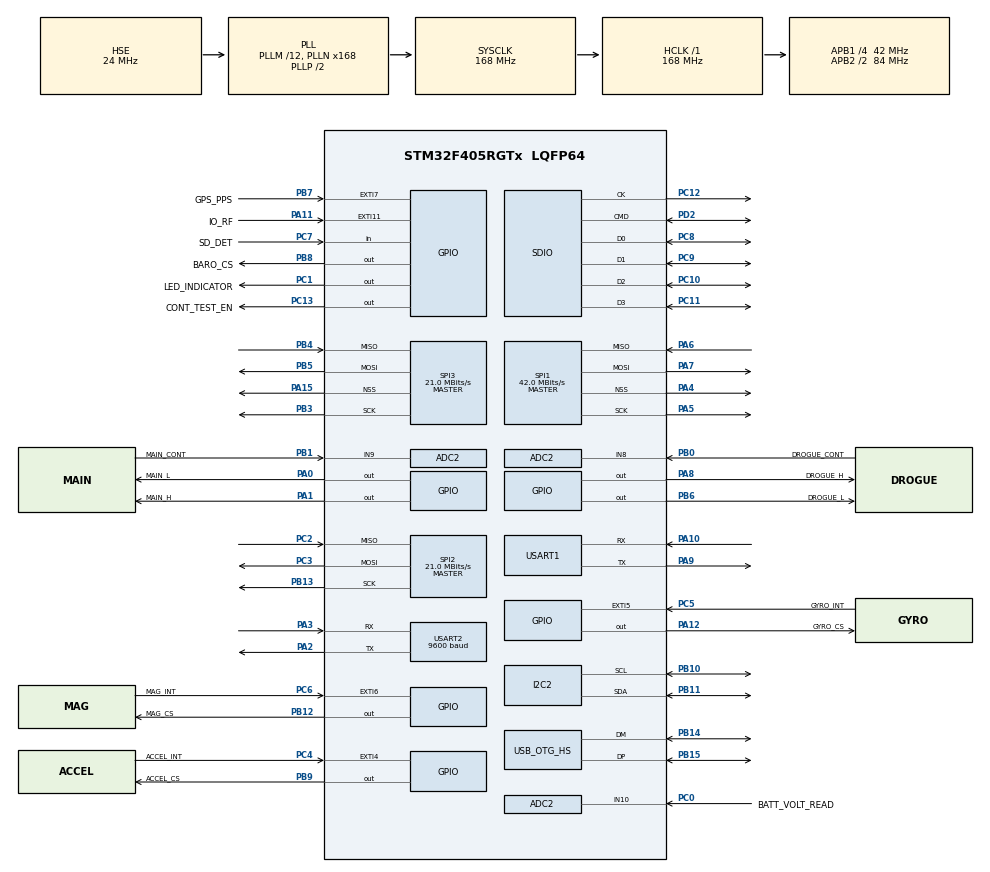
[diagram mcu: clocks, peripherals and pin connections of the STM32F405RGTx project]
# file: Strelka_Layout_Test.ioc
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ADC2.Channel-0\#ChannelRegularConversion=ADC_CHANNEL_8
ADC2.NbrOfConversionFlag=1
ADC2.Rank-0\#ChannelRegularConversion=1
ADC2.SamplingTime-0\#ChannelRegularConversion=ADC_SAMPLETIME_3CYCLES
FATFS.BSP.number=1
FATFS0.BSP.STBoard=false
FATFS0.BSP.api=Unknown
FATFS0.BSP.instance=PC7
FATFS0.BSP.ip=GPIO
FATFS0.BSP.mode=Input
FATFS0.BSP.name=Detect_SDIO
FATFS0.BSP.solution=PC7
FREERTOS.Tasks01=defaultTask,24,128,StartDefaultTask,Default,NULL,Dynamic,NULL,NULL
I2C2.I2C_Mode=I2C_Fast
Mcu.Family=STM32F4
Mcu.Name=STM32F405RGTx
Mcu.Package=LQFP64
NVIC.OTG_HS_IRQn=true\:5\:0\:false\:false\:true\:true\:false\:true\:true
NVIC.PriorityGroup=NVIC_PRIORITYGROUP_4
PA0-WKUP.GPIO_Label=MAIN_L
PA0-WKUP.Signal=GPIO_Output
PA1.GPIO_Label=MAIN_H
PA1.Signal=GPIO_Output
PA10.Mode=Asynchronous
PA10.Signal=USART1_RX
PA11.GPIO_Label=IO_RF
PA11.Signal=GPXTI11
PA12.GPIO_Label=GYRO_CS
PA12.Signal=GPIO_Output
PA13.Mode=Serial_Wire
PA13.Signal=SYS_JTMS-SWDIO
PA14.Mode=Serial_Wire
PA14.Signal=SYS_JTCK-SWCLK
PA15.Mode=NSS_Signal_Hard_Output
PA15.Signal=SPI3_NSS
PA2.Mode=Asynchronous
PA2.Signal=USART2_TX
PA3.Mode=Asynchronous
PA3.Signal=USART2_RX
PA4.Mode=NSS_Signal_Hard_Output
PA4.Signal=SPI1_NSS
PA5.Mode=Full_Duplex_Master
PA5.Signal=SPI1_SCK
PA6.Mode=Full_Duplex_Master
PA6.Signal=SPI1_MISO
PA7.Mode=Full_Duplex_Master
PA7.Signal=SPI1_MOSI
PA8.GPIO_Label=DROGUE_H
PA8.Signal=GPIO_Output
PA9.Mode=Asynchronous
PA9.Signal=USART1_TX
PB0.GPIO_Label=DROGUE_CONT
PB0.Signal=ADCx_IN8
PB1.GPIO_Label=MAIN_CONT
PB1.Signal=ADCx_IN9
PB10.Mode=I2C
PB10.Signal=I2C2_SCL
PB11.Mode=I2C
PB11.Signal=I2C2_SDA
PB12.GPIO_Label=MAG_CS
PB12.Signal=GPIO_Output
PB13.Mode=Full_Duplex_Master
PB13.Signal=SPI2_SCK
PB14.Mode=Device_Only_FS
PB14.Signal=USB_OTG_HS_DM
PB15.Mode=Device_Only_FS
PB15.Signal=USB_OTG_HS_DP
PB3.Mode=Full_Duplex_Master
PB3.Signal=SPI3_SCK
PB4.Mode=Full_Duplex_Master
PB4.Signal=SPI3_MISO
PB5.Mode=Full_Duplex_Master
PB5.Signal=SPI3_MOSI
PB6.GPIO_Label=DROGUE_L
PB6.Signal=GPIO_Output
PB7.GPIO_Label=GPS_PPS
PB7.Signal=GPXTI7
PB8.GPIO_Label=BARO_CS
PB8.Signal=GPIO_Output
PB9.GPIO_Label=ACCEL_CS
PB9.Signal=GPIO_Output
PC0.GPIO_Label=BATT_VOLT_READ
PC0.Signal=ADCx_IN10
PC1.GPIO_Label=LED_INDICATOR
PC1.Signal=GPIO_Output
PC10.Mode=SD_4_bits_Wide_bus
PC10.Signal=SDIO_D2
PC11.Mode=SD_4_bits_Wide_bus
PC11.Signal=SDIO_D3
PC12.Mode=SD_4_bits_Wide_bus
PC12.Signal=SDIO_CK
PC13-ANTI_TAMP.GPIO_Label=CONT_TEST_EN
PC13-ANTI_TAMP.Signal=GPIO_Output
PC14-OSC32_IN.Mode=LSE-External-Oscillator
PC14-OSC32_IN.Signal=RCC_OSC32_IN
PC15-OSC32_OUT.Mode=LSE-External-Oscillator
PC15-OSC32_OUT.Signal=RCC_OSC32_OUT
PC2.Mode=Full_Duplex_Master
PC2.Signal=SPI2_MISO
PC3.Mode=Full_Duplex_Master
PC3.Signal=SPI2_MOSI
PC4.GPIO_Label=ACCEL_INT
PC4.Signal=GPXTI4
PC5.GPIO_Label=GYRO_INT
PC5.Signal=GPXTI5
PC6.GPIO_Label=MAG_INT
PC6.Signal=GPXTI6
PC7.GPIO_Label=SD_DET
PC7.Signal=GPIO_Input
PC8.Mode=SD_4_bits_Wide_bus
PC8.Signal=SDIO_D0
PC9.Mode=SD_4_bits_Wide_bus
PC9.Signal=SDIO_D1
PD2.Mode=SD_4_bits_Wide_bus
PD2.Signal=SDIO_CMD
PH0-OSC_IN.Mode=HSE-External-Oscillator
PH0-OSC_IN.Signal=RCC_OSC_IN
PH1-OSC_OUT.Mode=HSE-External-Oscillator
PH1-OSC_OUT.Signal=RCC_OSC_OUT
ProjectManager.HeapSize=0x200
ProjectManager.StackSize=0x400
ProjectManager.TargetToolchain=STM32CubeIDE
RCC.48MHZClocksFreq_Value=48000000
RCC.AHBFreq_Value=168000000
RCC.APB1CLKDivider=RCC_HCLK_DIV4
RCC.APB1Freq_Value=42000000
RCC.APB1TimFreq_Value=84000000
RCC.APB2CLKDivider=RCC_HCLK_DIV2
RCC.APB2Freq_Value=84000000
RCC.APB2TimFreq_Value=168000000
RCC.CortexFreq_Value=168000000
RCC.HCLKFreq_Value=168000000
RCC.HSE_VALUE=24000000
RCC.HSI_VALUE=16000000
RCC.PLLM=12
RCC.PLLN=168
RCC.PLLQ=7
RCC.SYSCLKFreq_VALUE=168000000
RCC.SYSCLKSource=RCC_SYSCLKSOURCE_PLLCLK
RCC.VCOOutputFreq_Value=336000000
SH.ADCx_IN10.0=ADC2_IN10,IN10
SH.ADCx_IN8.0=ADC2_IN8,IN8
SH.ADCx_IN9.0=ADC2_IN9,IN9
SPI1.BaudRatePrescaler=SPI_BAUDRATEPRESCALER_2
SPI1.CalculateBaudRate=42.0 MBits/s
SPI1.Direction=SPI_DIRECTION_2LINES
SPI1.Mode=SPI_MODE_MASTER
SPI1.VirtualNSS=VM_NSSHARD
SPI1.VirtualType=VM_MASTER
SPI2.BaudRatePrescaler=SPI_BAUDRATEPRESCALER_2
SPI2.CalculateBaudRate=21.0 MBits/s
SPI2.Direction=SPI_DIRECTION_2LINES
SPI2.Mode=SPI_MODE_MASTER
SPI2.VirtualType=VM_MASTER
SPI3.BaudRatePrescaler=SPI_BAUDRATEPRESCALER_2
SPI3.CRCCalculation=SPI_CRCCALCULATION_DISABLE
SPI3.CalculateBaudRate=21.0 MBits/s
SPI3.Direction=SPI_DIRECTION_2LINES
SPI3.Mode=SPI_MODE_MASTER
SPI3.VirtualNSS=VM_NSSHARD
SPI3.VirtualType=VM_MASTER
USART1.VirtualMode=VM_ASYNC
USART2.BaudRate=9600
USART2.VirtualMode=VM_ASYNC
USB_DEVICE.CLASS_NAME_HS=CDC
USB_DEVICE.VirtualMode-CDC_HS=Cdc
USB_DEVICE.VirtualModeHS=Cdc_HS
USB_OTG_HS.VirtualMode-Device_Only_FS=Device_Only_FS
VP_CRC_VS_CRC.Mode=CRC_Activate
VP_FATFS_VS_SDIO.Mode=SDIO
VP_FREERTOS_VS_CMSIS_V2.Mode=CMSIS_V2
VP_TIM3_VS_ClockSourceINT.Mode=Internal
VP_USB_DEVICE_VS_USB_DEVICE_CDC_HS.Mode=CDC_HS
board=custom

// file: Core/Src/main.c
/* USER CODE BEGIN Header */
/**
  ******************************************************************************
  * @file           : main.c
  * @brief          : Main program body
  ******************************************************************************
  * @attention
  *
  * Copyright (c) 2022 STMicroelectronics.
  * All rights reserved.
  *
  * This software is licensed under terms that can be found in the LICENSE file
  * in the root directory of this software component.
  * If no LICENSE file comes with this software, it is provided AS-IS.
  *
  ******************************************************************************
  */
/* USER CODE END Header */
#include "main.h"
#include "cmsis_os.h"
#include "fatfs.h"
#include "usb_device.h"

/* USER CODE BEGIN Includes */
#include "actuator_control.h"
#include "bmx055.h"
#include "data_logging.h"
#include "Ematch_actuators.h"
#include "max_m10.h"
#include "ms5611.h"
/* USER CODE END Includes */

ADC_HandleTypeDef hadc2;

CRC_HandleTypeDef hcrc;

I2C_HandleTypeDef hi2c2;

SD_HandleTypeDef hsd;

SPI_HandleTypeDef hspi1;
SPI_HandleTypeDef hspi2;
SPI_HandleTypeDef hspi3;

TIM_HandleTypeDef htim3;

UART_HandleTypeDef huart1;
UART_HandleTypeDef huart2;

/* Definitions for defaultTask */
osThreadId_t defaultTaskHandle;
const osThreadAttr_t defaultTask_attributes = {
  .name = "defaultTask",
  .stack_size = 128 * 4,
  .priority = (osPriority_t) osPriorityNormal,
};

void SystemClock_Config(void);
static void MX_GPIO_Init(void);
static void MX_SDIO_SD_Init(void);
static void MX_SPI1_Init(void);
static void MX_SPI2_Init(void);
static void MX_USART1_UART_Init(void);
static void MX_TIM3_Init(void);
static void MX_I2C2_Init(void);
static void MX_ADC2_Init(void);
static void MX_SPI3_Init(void);
static void MX_USART2_UART_Init(void);
static void MX_CRC_Init(void);
void StartDefaultTask(void *argument);

int main(void)
{

  /* MCU Configuration--------------------------------------------------------*/

  /* Reset of all peripherals, Initializes the Flash interface and the Systick. */
  HAL_Init();

  /* Configure the system clock */
  SystemClock_Config();

  /* Initialize all configured peripherals */
  MX_GPIO_Init();
  MX_SDIO_SD_Init();
  MX_SPI1_Init();
  MX_SPI2_Init();
  MX_USART1_UART_Init();
  MX_TIM3_Init();
  MX_FATFS_Init();
  MX_I2C2_Init();
  MX_ADC2_Init();
  MX_SPI3_Init();
  MX_USART2_UART_Init();
  MX_CRC_Init();

  /* Init scheduler */
  osKernelInitialize();

  /* Create the thread(s) */
  /* creation of defaultTask */
  defaultTaskHandle = osThreadNew(StartDefaultTask, NULL, &defaultTask_attributes);

  /* Start scheduler */
  osKernelStart();

  /* We should never get here as control is now taken by the scheduler */
  /* Infinite loop */
  while (1)
  {

  }
}

void SystemClock_Config(void)
{
  RCC_OscInitTypeDef RCC_OscInitStruct = {0};
  RCC_ClkInitTypeDef RCC_ClkInitStruct = {0};

  /** Configure the main internal regulator output voltage
  */
  __HAL_RCC_PWR_CLK_ENABLE();
  __HAL_PWR_VOLTAGESCALING_CONFIG(PWR_REGULATOR_VOLTAGE_SCALE1);

  /** Initializes the RCC Oscillators according to the specified parameters
  * in the RCC_OscInitTypeDef structure.
  */
  RCC_OscInitStruct.OscillatorType = RCC_OSCILLATORTYPE_HSE;
  RCC_OscInitStruct.HSEState = RCC_HSE_ON;
  RCC_OscInitStruct.PLL.PLLState = RCC_PLL_ON;
  RCC_OscInitStruct.PLL.PLLSource = RCC_PLLSOURCE_HSE;
  RCC_OscInitStruct.PLL.PLLM = 12;
  RCC_OscInitStruct.PLL.PLLN = 168;
  RCC_OscInitStruct.PLL.PLLP = RCC_PLLP_DIV2;
  RCC_OscInitStruct.PLL.PLLQ = 7;
  if (HAL_RCC_OscConfig(&RCC_OscInitStruct) != HAL_OK)
  {
    Error_Handler();
  }

  /** Initializes the CPU, AHB and APB buses clocks
  */
  RCC_ClkInitStruct.ClockType = RCC_CLOCKTYPE_HCLK|RCC_CLOCKTYPE_SYSCLK
                              |RCC_CLOCKTYPE_PCLK1|RCC_CLOCKTYPE_PCLK2;
  RCC_ClkInitStruct.SYSCLKSource = RCC_SYSCLKSOURCE_PLLCLK;
  RCC_ClkInitStruct.AHBCLKDivider = RCC_SYSCLK_DIV1;
  RCC_ClkInitStruct.APB1CLKDivider = RCC_HCLK_DIV4;
  RCC_ClkInitStruct.APB2CLKDivider = RCC_HCLK_DIV2;

  if (HAL_RCC_ClockConfig(&RCC_ClkInitStruct, FLASH_LATENCY_5) != HAL_OK)
  {
    Error_Handler();
  }
}

static void MX_ADC2_Init(void)
{

  ADC_ChannelConfTypeDef sConfig = {0};

  /** Configure the global features of the ADC (Clock, Resolution, Data Alignment and number of conversion)
  */
  hadc2.Instance = ADC2;
  hadc2.Init.ClockPrescaler = ADC_CLOCK_SYNC_PCLK_DIV4;
  hadc2.Init.Resolution = ADC_RESOLUTION_12B;
  hadc2.Init.ScanConvMode = DISABLE;
  hadc2.Init.ContinuousConvMode = DISABLE;
  hadc2.Init.DiscontinuousConvMode = DISABLE;
  hadc2.Init.ExternalTrigConvEdge = ADC_EXTERNALTRIGCONVEDGE_NONE;
  hadc2.Init.ExternalTrigConv = ADC_SOFTWARE_START;
  hadc2.Init.DataAlign = ADC_DATAALIGN_RIGHT;
  hadc2.Init.NbrOfConversion = 1;
  hadc2.Init.DMAContinuousRequests = DISABLE;
  hadc2.Init.EOCSelection = ADC_EOC_SINGLE_CONV;
  if (HAL_ADC_Init(&hadc2) != HAL_OK)
  {
    Error_Handler();
  }

  /** Configure for the selected ADC regular channel its corresponding rank in the sequencer and its sample time.
  */
  sConfig.Channel = ADC_CHANNEL_8;
  sConfig.Rank = 1;
  sConfig.SamplingTime = ADC_SAMPLETIME_3CYCLES;
  if (HAL_ADC_ConfigChannel(&hadc2, &sConfig) != HAL_OK)
  {
    Error_Handler();
  }

}

static void MX_CRC_Init(void)
{

  hcrc.Instance = CRC;
  if (HAL_CRC_Init(&hcrc) != HAL_OK)
  {
    Error_Handler();
  }

}

static void MX_I2C2_Init(void)
{

  hi2c2.Instance = I2C2;
  hi2c2.Init.ClockSpeed = 400000;
  hi2c2.Init.DutyCycle = I2C_DUTYCYCLE_2;
  hi2c2.Init.OwnAddress1 = 0;
  hi2c2.Init.AddressingMode = I2C_ADDRESSINGMODE_7BIT;
  hi2c2.Init.DualAddressMode = I2C_DUALADDRESS_DISABLE;
  hi2c2.Init.OwnAddress2 = 0;
  hi2c2.Init.GeneralCallMode = I2C_GENERALCALL_DISABLE;
  hi2c2.Init.NoStretchMode = I2C_NOSTRETCH_DISABLE;
  if (HAL_I2C_Init(&hi2c2) != HAL_OK)
  {
    Error_Handler();
  }

}

static void MX_SDIO_SD_Init(void)
{

  hsd.Instance = SDIO;
  hsd.Init.ClockEdge = SDIO_CLOCK_EDGE_RISING;
  hsd.Init.ClockBypass = SDIO_CLOCK_BYPASS_DISABLE;
  hsd.Init.ClockPowerSave = SDIO_CLOCK_POWER_SAVE_DISABLE;
  hsd.Init.BusWide = SDIO_BUS_WIDE_1B;
  hsd.Init.HardwareFlowControl = SDIO_HARDWARE_FLOW_CONTROL_DISABLE;
  hsd.Init.ClockDiv = 0;

}

static void MX_SPI1_Init(void)
{

  /* SPI1 parameter configuration*/
  hspi1.Instance = SPI1;
  hspi1.Init.Mode = SPI_MODE_MASTER;
  hspi1.Init.Direction = SPI_DIRECTION_2LINES;
  hspi1.Init.DataSize = SPI_DATASIZE_8BIT;
  hspi1.Init.CLKPolarity = SPI_POLARITY_LOW;
  hspi1.Init.CLKPhase = SPI_PHASE_1EDGE;
  hspi1.Init.NSS = SPI_NSS_HARD_OUTPUT;
  hspi1.Init.BaudRatePrescaler = SPI_BAUDRATEPRESCALER_2;
  hspi1.Init.FirstBit = SPI_FIRSTBIT_MSB;
  hspi1.Init.TIMode = SPI_TIMODE_DISABLE;
  hspi1.Init.CRCCalculation = SPI_CRCCALCULATION_DISABLE;
  hspi1.Init.CRCPolynomial = 10;
  if (HAL_SPI_Init(&hspi1) != HAL_OK)
  {
    Error_Handler();
  }

}

static void MX_SPI2_Init(void)
{

  /* SPI2 parameter configuration*/
  hspi2.Instance = SPI2;
  hspi2.Init.Mode = SPI_MODE_MASTER;
  hspi2.Init.Direction = SPI_DIRECTION_2LINES;
  hspi2.Init.DataSize = SPI_DATASIZE_8BIT;
  hspi2.Init.CLKPolarity = SPI_POLARITY_LOW;
  hspi2.Init.CLKPhase = SPI_PHASE_1EDGE;
  hspi2.Init.NSS = SPI_NSS_SOFT;
  hspi2.Init.BaudRatePrescaler = SPI_BAUDRATEPRESCALER_2;
  hspi2.Init.FirstBit = SPI_FIRSTBIT_MSB;
  hspi2.Init.TIMode = SPI_TIMODE_DISABLE;
  hspi2.Init.CRCCalculation = SPI_CRCCALCULATION_DISABLE;
  hspi2.Init.CRCPolynomial = 10;
  if (HAL_SPI_Init(&hspi2) != HAL_OK)
  {
    Error_Handler();
  }

}

static void MX_SPI3_Init(void)
{

  /* SPI3 parameter configuration*/
  hspi3.Instance = SPI3;
  hspi3.Init.Mode = SPI_MODE_MASTER;
  hspi3.Init.Direction = SPI_DIRECTION_2LINES;
  hspi3.Init.DataSize = SPI_DATASIZE_8BIT;
  hspi3.Init.CLKPolarity = SPI_POLARITY_LOW;
  hspi3.Init.CLKPhase = SPI_PHASE_1EDGE;
  hspi3.Init.NSS = SPI_NSS_HARD_OUTPUT;
  hspi3.Init.BaudRatePrescaler = SPI_BAUDRATEPRESCALER_2;
  hspi3.Init.FirstBit = SPI_FIRSTBIT_MSB;
  hspi3.Init.TIMode = SPI_TIMODE_DISABLE;
  hspi3.Init.CRCCalculation = SPI_CRCCALCULATION_DISABLE;
  hspi3.Init.CRCPolynomial = 10;
  if (HAL_SPI_Init(&hspi3) != HAL_OK)
  {
    Error_Handler();
  }

}

static void MX_TIM3_Init(void)
{

  TIM_ClockConfigTypeDef sClockSourceConfig = {0};
  TIM_MasterConfigTypeDef sMasterConfig = {0};

  htim3.Instance = TIM3;
  htim3.Init.Prescaler = 0;
  htim3.Init.CounterMode = TIM_COUNTERMODE_UP;
  htim3.Init.Period = 65535;
  htim3.Init.ClockDivision = TIM_CLOCKDIVISION_DIV1;
  htim3.Init.AutoReloadPreload = TIM_AUTORELOAD_PRELOAD_DISABLE;
  if (HAL_TIM_Base_Init(&htim3) != HAL_OK)
  {
    Error_Handler();
  }
  sClockSourceConfig.ClockSource = TIM_CLOCKSOURCE_INTERNAL;
  if (HAL_TIM_ConfigClockSource(&htim3, &sClockSourceConfig) != HAL_OK)
  {
    Error_Handler();
  }
  sMasterConfig.MasterOutputTrigger = TIM_TRGO_RESET;
  sMasterConfig.MasterSlaveMode = TIM_MASTERSLAVEMODE_DISABLE;
  if (HAL_TIMEx_MasterConfigSynchronization(&htim3, &sMasterConfig) != HAL_OK)
  {
    Error_Handler();
  }

}

static void MX_USART1_UART_Init(void)
{

  huart1.Instance = USART1;
  huart1.Init.BaudRate = 115200;
  huart1.Init.WordLength = UART_WORDLENGTH_8B;
  huart1.Init.StopBits = UART_STOPBITS_1;
  huart1.Init.Parity = UART_PARITY_NONE;
  huart1.Init.Mode = UART_MODE_TX_RX;
  huart1.Init.HwFlowCtl = UART_HWCONTROL_NONE;
  huart1.Init.OverSampling = UART_OVERSAMPLING_16;
  if (HAL_UART_Init(&huart1) != HAL_OK)
  {
    Error_Handler();
  }

}

static void MX_USART2_UART_Init(void)
{

  huart2.Instance = USART2;
  huart2.Init.BaudRate = 9600;
  huart2.Init.WordLength = UART_WORDLENGTH_8B;
  huart2.Init.StopBits = UART_STOPBITS_1;
  huart2.Init.Parity = UART_PARITY_NONE;
  huart2.Init.Mode = UART_MODE_TX_RX;
  huart2.Init.HwFlowCtl = UART_HWCONTROL_NONE;
  huart2.Init.OverSampling = UART_OVERSAMPLING_16;
  if (HAL_UART_Init(&huart2) != HAL_OK)
  {
    Error_Handler();
  }

}

static void MX_GPIO_Init(void)
{
  GPIO_InitTypeDef GPIO_InitStruct = {0};

  /* GPIO Ports Clock Enable */
  __HAL_RCC_GPIOC_CLK_ENABLE();
  __HAL_RCC_GPIOH_CLK_ENABLE();
  __HAL_RCC_GPIOA_CLK_ENABLE();
  __HAL_RCC_GPIOB_CLK_ENABLE();
  __HAL_RCC_GPIOD_CLK_ENABLE();

  /*Configure GPIO pin Output Level */
  HAL_GPIO_WritePin(GPIOC, CONT_TEST_EN_Pin|LED_INDICATOR_Pin, GPIO_PIN_RESET);

  /*Configure GPIO pin Output Level */
  HAL_GPIO_WritePin(GPIOA, MAIN_L_Pin|MAIN_H_Pin|DROGUE_H_Pin|GYRO_CS_Pin, GPIO_PIN_RESET);

  /*Configure GPIO pin Output Level */
  HAL_GPIO_WritePin(GPIOB, MAG_CS_Pin|DROGUE_L_Pin|BARO_CS_Pin|ACCEL_CS_Pin, GPIO_PIN_RESET);

  /*Configure GPIO pins : CONT_TEST_EN_Pin LED_INDICATOR_Pin */
  GPIO_InitStruct.Pin = CONT_TEST_EN_Pin|LED_INDICATOR_Pin;
  GPIO_InitStruct.Mode = GPIO_MODE_OUTPUT_PP;
  GPIO_InitStruct.Pull = GPIO_NOPULL;
  GPIO_InitStruct.Speed = GPIO_SPEED_FREQ_LOW;
  HAL_GPIO_Init(GPIOC, &GPIO_InitStruct);

  /*Configure GPIO pins : MAIN_L_Pin MAIN_H_Pin DROGUE_H_Pin GYRO_CS_Pin */
  GPIO_InitStruct.Pin = MAIN_L_Pin|MAIN_H_Pin|DROGUE_H_Pin|GYRO_CS_Pin;
  GPIO_InitStruct.Mode = GPIO_MODE_OUTPUT_PP;
  GPIO_InitStruct.Pull = GPIO_NOPULL;
  GPIO_InitStruct.Speed = GPIO_SPEED_FREQ_LOW;
  HAL_GPIO_Init(GPIOA, &GPIO_InitStruct);

  /*Configure GPIO pins : ACCEL_INT_Pin GYRO_INT_Pin MAG_INT_Pin */
  GPIO_InitStruct.Pin = ACCEL_INT_Pin|GYRO_INT_Pin|MAG_INT_Pin;
  GPIO_InitStruct.Mode = GPIO_MODE_IT_RISING;
  GPIO_InitStruct.Pull = GPIO_NOPULL;
  HAL_GPIO_Init(GPIOC, &GPIO_InitStruct);

  /*Configure GPIO pins : MAG_CS_Pin DROGUE_L_Pin BARO_CS_Pin ACCEL_CS_Pin */
  GPIO_InitStruct.Pin = MAG_CS_Pin|DROGUE_L_Pin|BARO_CS_Pin|ACCEL_CS_Pin;
  GPIO_InitStruct.Mode = GPIO_MODE_OUTPUT_PP;
  GPIO_InitStruct.Pull = GPIO_NOPULL;
  GPIO_InitStruct.Speed = GPIO_SPEED_FREQ_LOW;
  HAL_GPIO_Init(GPIOB, &GPIO_InitStruct);

  /*Configure GPIO pin : SD_DET_Pin */
  GPIO_InitStruct.Pin = SD_DET_Pin;
  GPIO_InitStruct.Mode = GPIO_MODE_INPUT;
  GPIO_InitStruct.Pull = GPIO_NOPULL;
  HAL_GPIO_Init(SD_DET_GPIO_Port, &GPIO_InitStruct);

  /*Configure GPIO pin : IO_RF_Pin */
  GPIO_InitStruct.Pin = IO_RF_Pin;
  GPIO_InitStruct.Mode = GPIO_MODE_IT_RISING;
  GPIO_InitStruct.Pull = GPIO_NOPULL;
  HAL_GPIO_Init(IO_RF_GPIO_Port, &GPIO_InitStruct);

  /*Configure GPIO pin : GPS_PPS_Pin */
  GPIO_InitStruct.Pin = GPS_PPS_Pin;
  GPIO_InitStruct.Mode = GPIO_MODE_IT_RISING;
  GPIO_InitStruct.Pull = GPIO_NOPULL;
  HAL_GPIO_Init(GPS_PPS_GPIO_Port, &GPIO_InitStruct);

}

void StartDefaultTask(void *argument)
{
  /* init code for USB_DEVICE */
  MX_USB_DEVICE_Init();
  for(;;)
  {
    osDelay(1);
  }
}

void Error_Handler(void)
{
  __disable_irq();
  while (1)
  {
  }
}
